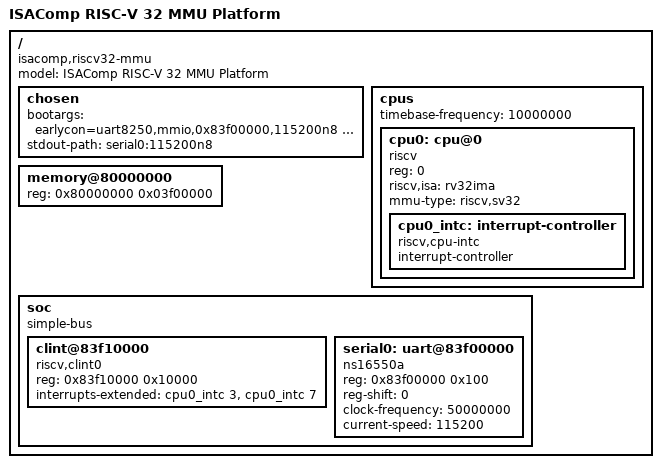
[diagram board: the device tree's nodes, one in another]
/dts-v1/;

/ {
    #address-cells = <1>;
    #size-cells = <1>;
    compatible = "isacomp,riscv32-mmu";
    model = "ISAComp RISC-V 32 MMU Platform";

    chosen {
        bootargs = "earlycon=uart8250,mmio,0x83f00000,115200n8 console=ttyS0";
        stdout-path = "serial0:115200n8";
    };

    cpus {
        #address-cells = <1>;
        #size-cells = <0>;
        timebase-frequency = <10000000>;  // 10 MHz timer

        cpu0: cpu@0 {
            device_type = "cpu";
            reg = <0>;
            compatible = "riscv";
            riscv,isa = "rv32ima";
            mmu-type = "riscv,sv32";

            cpu0_intc: interrupt-controller {
                #interrupt-cells = <1>;
                interrupt-controller;
                compatible = "riscv,cpu-intc";
            };
        };
    };

    memory@80000000 {
        device_type = "memory";
        reg = <0x80000000 0x03f00000>;  // 63MB at 0x80000000 (last 1MB reserved for peripherals)
    };

    soc {
        #address-cells = <1>;
        #size-cells = <1>;
        compatible = "simple-bus";
        ranges;

        clint@83f10000 {
            compatible = "riscv,clint0";
            reg = <0x83f10000 0x10000>;  // In reserved last 1MB
            interrupts-extended = <&cpu0_intc 3 &cpu0_intc 7>;  // M-mode SW and timer
        };

        serial0: uart@83f00000 {
            compatible = "ns16550a";
            reg = <0x83f00000 0x100>;  // In reserved last 1MB
            reg-shift = <0>;
            clock-frequency = <50000000>;  // 50 MHz
            current-speed = <115200>;
            // No interrupts for now - polling mode
        };
    };
};
